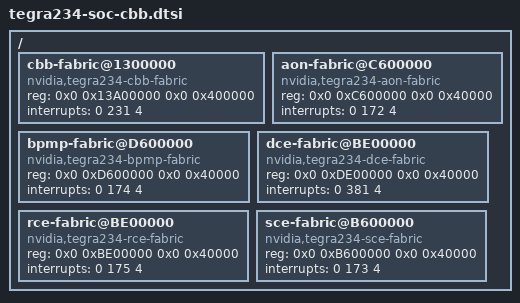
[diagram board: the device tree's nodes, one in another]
/*
 * Copyright (c) 2019-2020, NVIDIA CORPORATION.  All rights reserved.
 *
 * This program is free software; you can redistribute it and/or modify it
 * under the terms and conditions of the GNU General Public License,
 * version 2, as published by the Free Software Foundation.
 *
 * This program is distributed in the hope it will be useful, but WITHOUT
 * ANY WARRANTY; without even the implied warranty of MERCHANTABILITY or
 * FITNESS FOR A PARTICULAR PURPOSE.  See the GNU General Public License for
 * more details.
 *
 * You should have received a copy of the GNU General Public License
 * along with this program.  If not, see <http://www.gnu.org/licenses/>.
 */

/ {
	cbb-fabric@1300000 {
		compatible = "nvidia,tegra234-cbb-fabric";
		reg = <0x0 0x13A00000 0x0 0x400000>;
		interrupts = <0 231 4>;
		status = "okay";
	};

	aon-fabric@C600000 {
		compatible = "nvidia,tegra234-aon-fabric";
		reg = <0x0 0xC600000 0x0 0x40000>;
		interrupts = <0 172 4>;
		status = "okay";
	};

	bpmp-fabric@D600000 {
		compatible = "nvidia,tegra234-bpmp-fabric";
		reg = <0x0 0xD600000 0x0 0x40000>;
		interrupts = <0 174 4>;
		status = "okay";
	};

	dce-fabric@BE00000 {
		compatible = "nvidia,tegra234-dce-fabric";
		reg = <0x0 0xDE00000 0x0 0x40000>;
		interrupts = <0 381 4>;
		status = "okay";
	};

	rce-fabric@BE00000 {
		compatible = "nvidia,tegra234-rce-fabric";
		reg = <0x0 0xBE00000 0x0 0x40000>;
		interrupts = <0 175 4>;
		status = "okay";
	};

	sce-fabric@B600000 {
		compatible = "nvidia,tegra234-sce-fabric";
		reg = <0x0 0xB600000 0x0 0x40000>;
		interrupts = <0 173 4>;
		status = "okay";
	};

};
